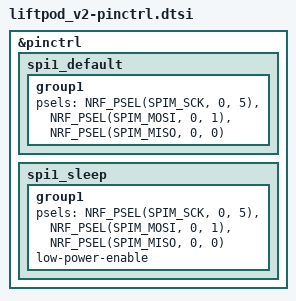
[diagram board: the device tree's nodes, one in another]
&pinctrl {
	spi1_default: spi1_default {
		group1 {
			psels = <NRF_PSEL(SPIM_SCK, 0, 5)>,
				<NRF_PSEL(SPIM_MOSI, 0, 1)>,
				<NRF_PSEL(SPIM_MISO, 0, 0)>;
		};
	};

	spi1_sleep: spi1_sleep {
		group1 {
			psels = <NRF_PSEL(SPIM_SCK, 0, 5)>,
				<NRF_PSEL(SPIM_MOSI, 0, 1)>,
				<NRF_PSEL(SPIM_MISO, 0, 0)>;
			low-power-enable;
		};
	};
};
